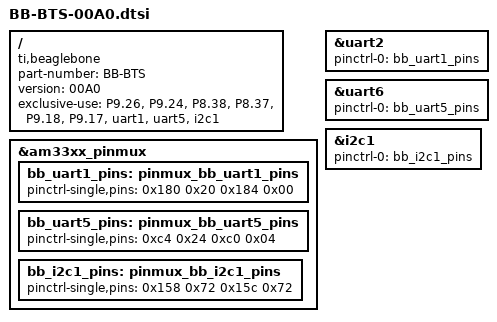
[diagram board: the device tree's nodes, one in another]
/dts-v1/;
/plugin/;

/ {
    compatible = "ti,beaglebone", "ti,beaglebone-black";

    part-number = "BB-BTS";
    version = "00A0";
    exclusive-use = 
        "P9.26", 
        "P9.24", 
        "P8.38", 
        "P8.37", 
        "P9.18", 
        "P9.17", 
        "uart1",
        "uart5",
        "i2c1";
    fragment@0 {
        target = <&am33xx_pinmux>;
        __overlay__{
            bb_uart1_pins: pinmux_bb_uart1_pins {
                pinctrl-single,pins = <
               0x180 0x20
               0x184 0x00
                >;
           };
        };
    };
    fragment@1 {
        target = <&uart2>;
        __overlay__{
            status = "okay";
            pinctrl-names = "default";
            pinctrl-0 = <&bb_uart1_pins>;
        };
    };
    fragment@2 {
        target = <&am33xx_pinmux>;
        __overlay__{
            bb_uart5_pins: pinmux_bb_uart5_pins {
                pinctrl-single,pins = <
               0xc4 0x24
               0xc0 0x04
                >;
           };
        };
    };
    fragment@3 {
        target = <&uart6>;
        __overlay__{
            status = "okay";
            pinctrl-names = "default";
            pinctrl-0 = <&bb_uart5_pins>;
        };
    };
    fragment@4 {
        target = <&am33xx_pinmux>;
        __overlay__{
            bb_i2c1_pins: pinmux_bb_i2c1_pins {
                pinctrl-single,pins = <
               0x158 0x72
               0x15c 0x72
                >;
           };
        };
    };
    fragment@5 {
        target = <&i2c1>;
        __overlay__{
            status = "okay";
            pinctrl-names = "default";
            pinctrl-0 = <&bb_i2c1_pins>;
        };
    };

};
